# STM32H753 register map
File version: 1.9
CPU: CM7 r0p1, little endian, MPU, FPU, 4 interrupt priority bits
Registers are 32-bit, read-write, reset 0x0 unless marked. A register's access mark holds for its fields unless they carry their own. Offsets are from the block's base; [hi:lo] are bit positions; {n}, {i} and the like mark numbered series; 'fields as' and 'values as' point back to an identical list.

## MDIOS — Management data input/output slave
Base 0x40009400
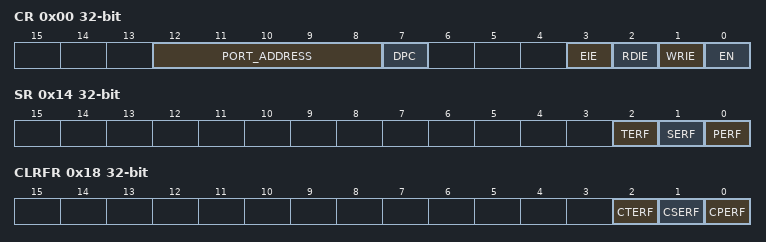
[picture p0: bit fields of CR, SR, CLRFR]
0x00 CR — MDIOS configuration register
  [12:8] PORT_ADDRESS — Slaves's address
  [7] DPC — Disable Preamble Check
  [3] EIE — Error interrupt enable
  [2] RDIE — Register Read Interrupt Enable
  [1] WRIE — Register write interrupt enable
  [0] EN — Peripheral enable
0x04 WRFR ro — MDIOS write flag register
  [31:0] WRF — Write flags for MDIO registers 0 to 31
0x08 CWRFR — MDIOS clear write flag register
  [31:0] CWRF — Clear the write flag
0x0C RDFR ro — MDIOS read flag register
  [31:0] RDF — Read flags for MDIO registers 0 to 31
0x10 CRDFR — MDIOS clear read flag register
  [31:0] CRDF — Clear the read flag
0x14 SR ro — MDIOS status register
  [2] TERF — Turnaround error flag
  [1] SERF — Start error flag
  [0] PERF — Preamble error flag
0x18 CLRFR — MDIOS clear flag register
  [2] CTERF — Clear the turnaround error flag
  [1] CSERF — Clear the start error flag
  [0] CPERF — Clear the preamble error flag
{0x1C+4i} DINR{i} ro (i=0..31) — MDIOS input data register {i}
  [15:0] DIN{i} — Input data received from MDIO Master during write frames
{0x9C+4i} DOUTR{i} (i=0..31) — MDIOS output data register {i}
  [15:0] DOUT{i} — Output data sent to MDIO Master during read frames

## OPAMP — Operational amplifiers
Base 0x40009000
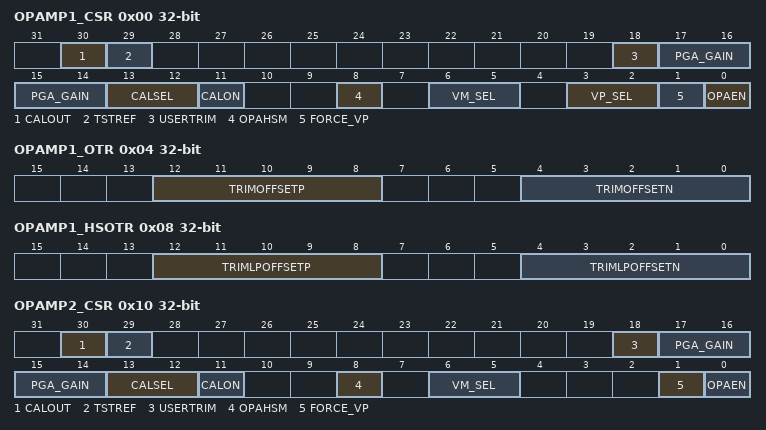
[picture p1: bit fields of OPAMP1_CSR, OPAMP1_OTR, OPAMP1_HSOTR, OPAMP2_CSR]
0x00 OPAMP1_CSR — OPAMP1 control/status register
  [30] CALOUT — Operational amplifier calibration output
  [29] TSTREF — OPAMP calibration reference voltage output control (reserved for test)
  [18] USERTRIM — User trimming enable
  [17:14] PGA_GAIN — allows to switch from AOP offset trimmed values to AOP offset
  [13:12] CALSEL — Calibration selection
  [11] CALON — Calibration mode enabled
  [8] OPAHSM — Operational amplifier high-speed mode
  [6:5] VM_SEL — Inverting input selection
  [3:2] VP_SEL — Operational amplifier PGA mode
  [1] FORCE_VP — Force internal reference on VP (reserved for test
  [0] OPAEN — Operational amplifier Enable
0x04 OPAMP1_OTR — OPAMP1 offset trimming register in normal mode
  [12:8] TRIMOFFSETP — Trim for PMOS differential pairs
  [4:0] TRIMOFFSETN — Trim for NMOS differential pairs
0x08 OPAMP1_HSOTR — OPAMP1 offset trimming register in low-power mode
  [12:8] TRIMLPOFFSETP — Trim for PMOS differential pairs
  [4:0] TRIMLPOFFSETN — Trim for NMOS differential pairs
0x10 OPAMP2_CSR — OPAMP2 control/status register
  [30] CALOUT — Operational amplifier calibration output
  [29] TSTREF — OPAMP calibration reference voltage output control (reserved for test)
  [18] USERTRIM — User trimming enable
  [17:14] PGA_GAIN — Operational amplifier Programmable amplifier gain value
  [13:12] CALSEL — Calibration selection
  [11] CALON — Calibration mode enabled
  [8] OPAHSM — Operational amplifier high-speed mode
  [6:5] VM_SEL — Inverting input selection
  [1] FORCE_VP — Force internal reference on VP (reserved for test)
  [0] OPAEN — Operational amplifier Enable
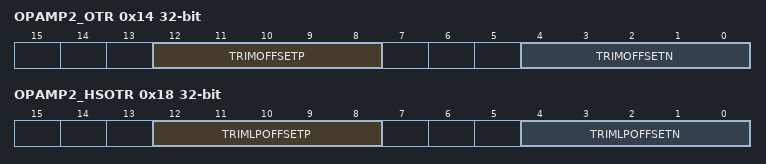
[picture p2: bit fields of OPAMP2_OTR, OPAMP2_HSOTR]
0x14 OPAMP2_OTR — OPAMP2 offset trimming register in normal mode
  fields as OPAMP1_OTR
0x18 OPAMP2_HSOTR — OPAMP2 offset trimming register in low-power mode
  fields as OPAMP1_HSOTR

## SWPMI — Single Wire Protocol Master Interface
Base 0x40008800
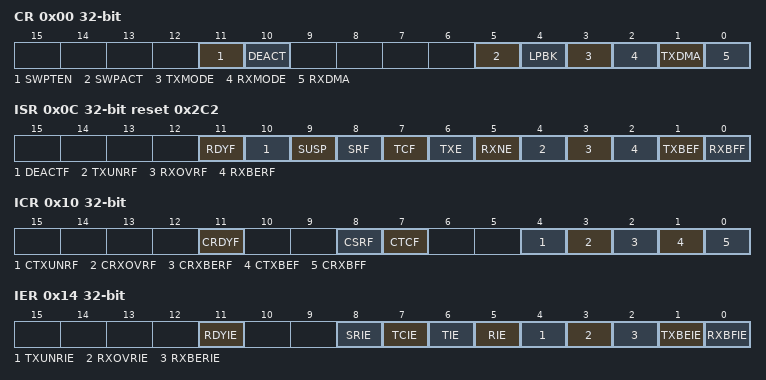
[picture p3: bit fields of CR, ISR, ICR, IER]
0x00 CR — SWPMI Configuration/Control register
  [11] SWPTEN — Single wire protocol master transceiver enable
  [10] DEACT — Single wire protocol master interface deactivate
  [5] SWPACT — Single wire protocol master interface activate
  [4] LPBK — Loopback mode enable
  [3] TXMODE — Transmission buffering mode
  [2] RXMODE — Reception buffering mode
  [1] TXDMA — Transmission DMA enable
  [0] RXDMA — Reception DMA enable
0x04 BRR reset 0x1 — SWPMI Bitrate register
  [7:0] BR — Bitrate prescaler
0x0C ISR ro reset 0x2C2 — SWPMI Interrupt and Status register
  [11] RDYF — transceiver ready flag
  [10] DEACTF — DEACTIVATED flag
  [9] SUSP — SUSPEND flag
  [8] SRF — Slave resume flag
  [7] TCF — Transfer complete flag
  [6] TXE — Transmit data register empty
  [5] RXNE — Receive data register not empty
  [4] TXUNRF — Transmit underrun error flag
  [3] RXOVRF — Receive overrun error flag
  [2] RXBERF — Receive CRC error flag
  [1] TXBEF — Transmit buffer empty flag
  [0] RXBFF — Receive buffer full flag
0x10 ICR wo — SWPMI Interrupt Flag Clear register
  [11] CRDYF — Clear transceiver ready flag
  [8] CSRF — Clear slave resume flag
  [7] CTCF — Clear transfer complete flag
  [4] CTXUNRF — Clear transmit underrun error flag
  [3] CRXOVRF — Clear receive overrun error flag
  [2] CRXBERF — Clear receive CRC error flag
  [1] CTXBEF — Clear transmit buffer empty flag
  [0] CRXBFF — Clear receive buffer full flag
0x14 IER — SWPMI Interrupt Enable register
  [11] RDYIE — Transceiver ready interrupt enable
  [8] SRIE — Slave resume interrupt enable
  [7] TCIE — Transmit complete interrupt enable
  [6] TIE — Transmit interrupt enable
  [5] RIE — Receive interrupt enable
  [4] TXUNRIE — Transmit underrun error interrupt enable
  [3] RXOVRIE — Receive overrun error interrupt enable
  [2] RXBERIE — Receive CRC error interrupt enable
  [1] TXBEIE — Transmit buffer empty interrupt enable
  [0] RXBFIE — Receive buffer full interrupt enable
0x18 RFL ro — SWPMI Receive Frame Length register
  [4:0] RFL — Receive frame length
0x1C TDR wo — SWPMI Transmit data register
  [31:0] TD — Transmit data
0x20 RDR ro — SWPMI Receive data register
  [31:0] RD — received data
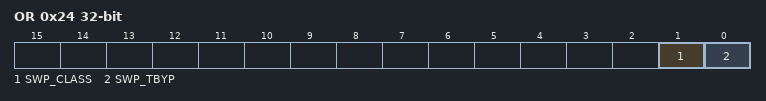
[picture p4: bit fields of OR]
0x24 OR — SWPMI Option register
  [1] SWP_CLASS — SWP class selection
  [0] SWP_TBYP — SWP transceiver bypass

## TIM6 — Basic timers
Base 0x40001000
Same registers: TIM7 0x40001400
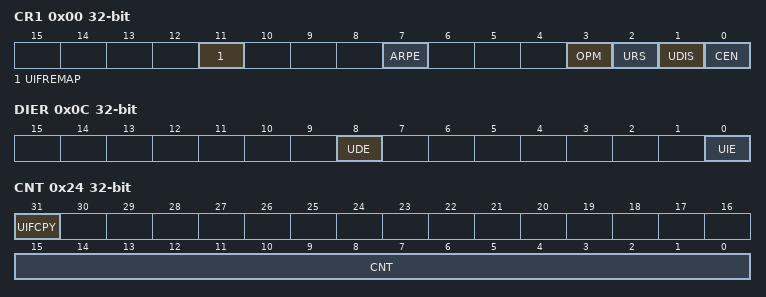
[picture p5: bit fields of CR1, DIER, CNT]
0x00 CR1 — control register 1
  [11] UIFREMAP — UIF status bit remapping
  [7] ARPE — Auto-reload preload enable
    0=Disabled (TIMx_APRR register is not buffered); 1=Enabled (TIMx_APRR register is buffered)
  [3] OPM — One-pulse mode
    0=Disabled (Counter is not stopped at update event); 1=Enabled (Counter stops counting at the next update event (clearing the CEN bit))
  [2] URS — Update request source
    0=AnyEvent (Any of counter overflow/underflow, setting UG, or update through slave mode, generates an update interrupt or DMA request); 1=CounterOnly (Only counter overflow/underflow generates an update interrupt or DMA request)
  [1] UDIS — Update disable
    0=Enabled (Update event enabled); 1=Disabled (Update event disabled)
  [0] CEN — Counter enable
    0=Disabled (Counter disabled); 1=Enabled (Counter enabled)
0x04 CR2 — control register 2
  [6:4] MMS — Master mode selection
    0=Reset (Use UG bit from TIMx_EGR register); 1=Enable (Use CNT bit from TIMx_CEN register); 2=Update (Use the update event)
0x0C DIER — DMA/Interrupt enable register
  [8] UDE — Update DMA request enable
    0=Disabled (Update DMA request disabled); 1=Enabled (Update DMA request enabled)
  [0] UIE — Update interrupt enable
    0=Disabled (Update interrupt disabled); 1=Enabled (Update interrupt enabled)
0x10 SR — status register
  [0] UIF write-0-clears — Update interrupt flag
    on read: 0=NoUpdateOccurred; 1=UpdatePending (Update interrupt pending) | on write: 0=Clear flag
0x14 EGR wo — event generation register
  [0] UG — Update generation
    1=Update (Re-initializes the timer counter and generates an update of the registers.)
0x24 CNT — counter
  [31] UIFCPY — UIF Copy
  [15:0] CNT — Low counter value
0x28 PSC — prescaler
  [15:0] PSC — Prescaler value
0x2C ARR — auto-reload register
  [15:0] ARR — Low Auto-reload value

## DBGMCU — Microcontroller Debug Unit
Base 0x5C001000
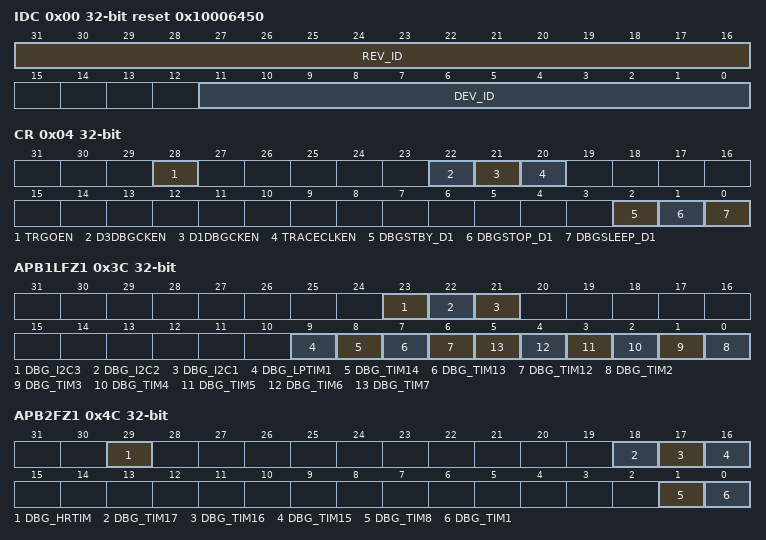
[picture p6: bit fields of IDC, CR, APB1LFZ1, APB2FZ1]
0x00 IDC ro reset 0x10006450 — DBGMCU Identity Code Register
  [31:16] REV_ID — Revision
  [11:0] DEV_ID — Device ID
0x04 CR — DBGMCU Configuration Register
  [28] TRGOEN — External trigger output enable
  [22] D3DBGCKEN — D3 debug clock enable
  [21] D1DBGCKEN — D1 debug clock enable
  [20] TRACECLKEN — Trace port clock enable
  [2] DBGSTBY_D1 — Allow D1 domain debug in Standby mode
  [1] DBGSTOP_D1 — Allow D1 domain debug in Stop mode
  [0] DBGSLEEP_D1 — Allow D1 domain debug in Sleep mode
0x34 APB3FZ1 — DBGMCU APB3 peripheral freeze register
  [6] WWDG1 — WWDG1 stop in debug
0x3C APB1LFZ1 — DBGMCU APB1L peripheral freeze register
  [23] DBG_I2C3 — I2C3 SMBUS timeout stop in debug
  [22] DBG_I2C2 — I2C2 SMBUS timeout stop in debug
  [21] DBG_I2C1 — I2C1 SMBUS timeout stop in debug
  [9] DBG_LPTIM1 — LPTIM1 stop in debug
  [8] DBG_TIM14 — TIM14 stop in debug
  [7] DBG_TIM13 — TIM13 stop in debug
  [6] DBG_TIM12 — TIM12 stop in debug
  [n-2] DBG_TIM{n} (n=2..7) — TIM{n} stop in debug
0x4C APB2FZ1 — DBGMCU APB2 peripheral freeze register
  [29] DBG_HRTIM — HRTIM stop in debug
  [18] DBG_TIM17 — TIM17 stop in debug
  [17] DBG_TIM16 — TIM16 stop in debug
  [16] DBG_TIM15 — TIM15 stop in debug
  [1] DBG_TIM8 — TIM8 stop in debug
  [0] DBG_TIM1 — TIM1 stop in debug
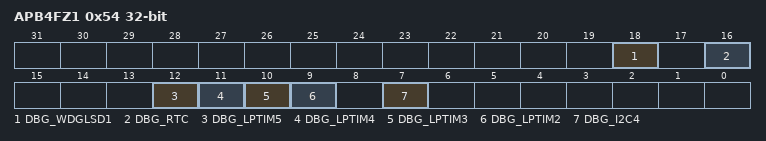
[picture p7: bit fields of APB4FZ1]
0x54 APB4FZ1 — DBGMCU APB4 peripheral freeze register
  [18] DBG_WDGLSD1 — Independent watchdog for D1 stop in debug
  [16] DBG_RTC — RTC stop in debug
  [12] DBG_LPTIM5 — LPTIM5 stop in debug
  [11] DBG_LPTIM4 — LPTIM4 stop in debug
  [10] DBG_LPTIM3 — LPTIM2 stop in debug
  [9] DBG_LPTIM2 — LPTIM2 stop in debug
  [7] DBG_I2C4 — I2C4 SMBUS timeout stop in debug
